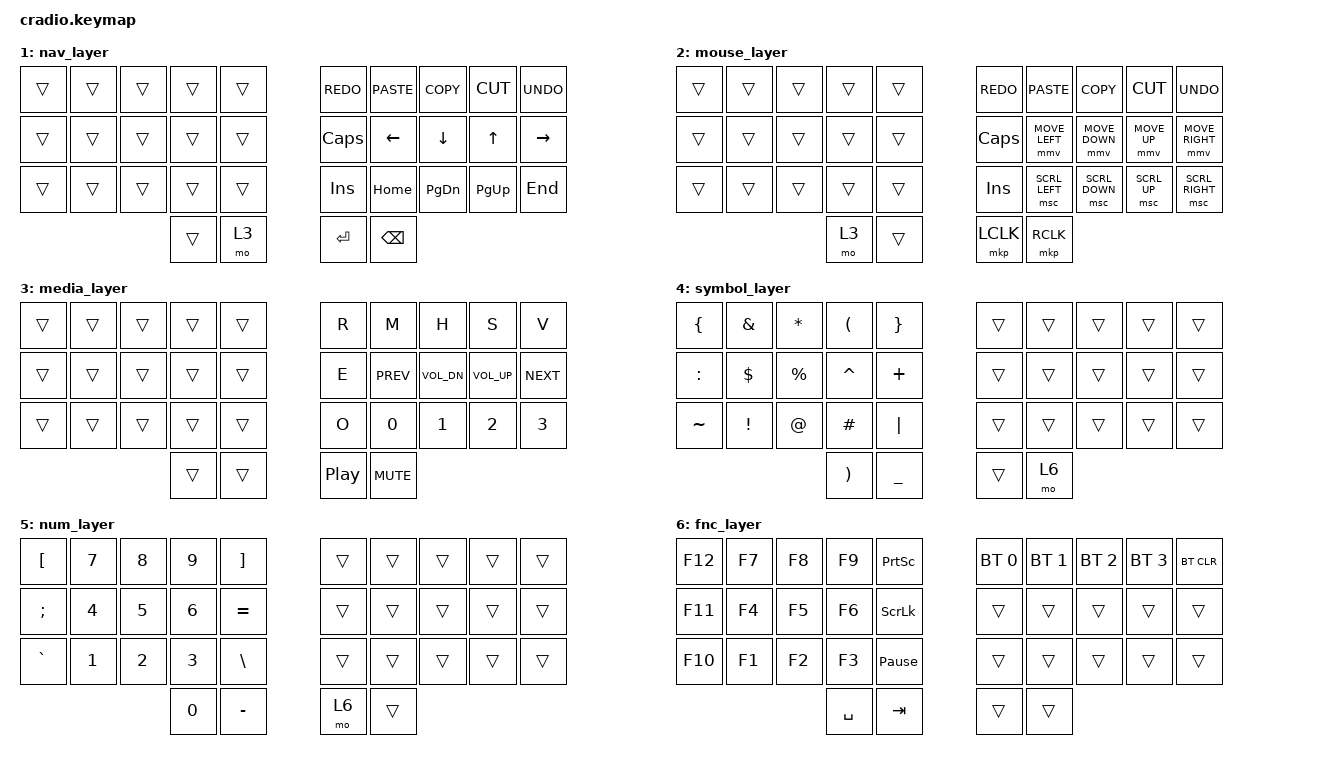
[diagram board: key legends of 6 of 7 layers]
// Copyright (c) 2022 The ZMK Contributors
// SPDX-License-Identifier: MIT

#include <behaviors.dtsi>
#include <dt-bindings/zmk/keys.h>
#include <dt-bindings/zmk/bt.h>
#include <dt-bindings/zmk/pointing.h>

// Home row mods macro
#define HRML(k1,k2,k3,k4) &ht LGUI k1  &ht LALT k2  &ht LCTRL k3  &ht LSHFT k4
#define HRMR(k1,k2,k3,k4) &ht RSHFT k1  &ht RCTRL k2  &ht RALT k3  &ht RGUI k4

/ {
    behaviors {
        ht: hold_tap {
            compatible = "zmk,behavior-hold-tap";
            #binding-cells = <2>;
            flavor = "tap-preferred";
            tapping-term-ms = <220>;
            quick-tap-ms = <150>;
            require-prior-idle-ms = <100>;
            bindings = <&kp>, <&kp>;
        };
    };


    combos {
                compatible = "zmk,combos";
                combo_esc {
                        timeout-ms = <75>;
                        key-positions = <0 1>;
                        bindings = <&kp ESC>;
                };
                combo_bksp {
                        timeout-ms = <75>;
                        key-positions = <8 9>;
                        bindings = <&kp BSPC>;
                };
                combo_entr {
                        timeout-ms = <75>;
                        key-positions = <28 29>;
                        bindings = <&kp RET>;
                };
                combo_tab {
                        timeout-ms = <75>;
                        key-positions = <20 21>;
                        bindings = <&kp TAB>;
                };
                //combo_mo_3 {
                //    timeout-ms = <75>;
                //    key-positions = <30, 31>;
                //    bindings = <&mo 3>;
                //};
                //combo_mo_6 {
                //    timeout-ms = <75>;
                //    key-positions = <32, 33>;
                //    bindings = <&mo 6>;
                //};
        };

    keymap {
        compatible = "zmk,keymap";
        default_layer {
            bindings = <
        //╭──────────┬──────────┬──────────┬──────────┬──────────╮   ╭──────────┬──────────┬──────────┬──────────┬──────────╮
        //│  Q       │  W       │  F       │  P       │  B       │   │  J       │  L       │  U       │  Y       │  '       │
            &kp Q      &kp W      &kp F      &kp P      &kp B          &kp J      &kp L      &kp U      &kp Y      &kp SQT
        //├──────────┼──────────┼──────────┼──────────┼──────────┤   ├──────────┼──────────┼──────────┼──────────┼──────────┤
        //│  A       │  R       │  S       │  T       │  G       │   │  M       │  N       │  E       │  I       │  O      │
            HRML(A,        R,         S,         T)     &kp G          &kp M      HRMR(N,        E,         I,        O)
        //├──────────┼──────────┼──────────┼──────────┼──────────┤   ├──────────┼──────────┼──────────┼──────────┼──────────┤
        //│  Z       │  X       │  C       │  D       │  V       │   │  K       │  H       │ , <      │ . >      │ / ?      │
            &kp Z      &kp X      &kp C      &kp D      &kp V          &kp K      &kp H      &kp COMMA  &kp DOT    &kp FSLH
        //╰──────────┴──────────┴──────────┼──────────┼──────────┤   ├──────────┼──────────┼──────────┴──────────┴──────────╯
                                            &lt 1 SPACE   &lt 2 TAB   &lt 4 ENTER  &lt 5 BSPC
        //                                 ╰──────────┴──────────╯   ╰──────────┴──────────╯
            >;
        };

        nav_layer {
            bindings = <
        //╭──────────┬──────────┬──────────┬──────────┬──────────╮   ╭──────────┬──────────┬──────────┬──────────┬──────────╮
        //│trans     │  trans   |          │          │          │   │ CUT     │ PAGE DN  │ PAGE UP  │ END      │  :       │
            &trans    &trans     &trans    &trans     &trans          &kp K_REDO &kp K_PASTE &kp K_COPY &kp K_CUT &kp K_UNDO
        //├──────────┼──────────┼──────────┼──────────┼──────────┤   ├──────────┼──────────┼──────────┼──────────┼──────────┤
        //│          │          │          │          │          │   │ LEFT     │ DOWN     │ UP       │ RIGHT    │  ;       │
            &trans    &trans     &trans     &trans     &trans         &kp CAPS  &kp LEFT   &kp DOWN   &kp UP   &kp RIGHT
        //├──────────┼──────────┼──────────┼──────────┼──────────┤   ├──────────┼──────────┼──────────┼──────────┼──────────┤
        //│          │          │          │          │          │   │          │          │          │          │          │
           &trans      &trans     &trans     &trans     &trans         &kp INS    &kp HOME   &kp PG_DN  &kp PG_UP  &kp END
        //╰──────────┴──────────┴──────────┼──────────┼──────────┤   ├──────────┼──────────┼──────────┴──────────┴──────────╯
                                             &trans     &mo 3        &kp ENTER   &kp BSPC
        //                                 ╰──────────┴──────────╯   ╰──────────┴──────────╯
            >;
        };

        mouse_layer {
            bindings = <
        //╭──────────┬──────────┬──────────┬──────────┬──────────╮   ╭──────────┬──────────┬──────────┬──────────┬──────────╮
        //│trans     │  trans   |          │          │          │   │ CUT     │ PAGE DN  │ PAGE UP  │ END      │  :       │
            &trans    &trans     &trans    &trans     &trans          &kp K_REDO &kp K_PASTE &kp K_COPY &kp K_CUT &kp K_UNDO
        //├──────────┼──────────┼──────────┼──────────┼──────────┤   ├──────────┼──────────┼──────────┼──────────┼──────────┤
        //│          │          │          │          │          │   │ LEFT     │ DOWN     │ UP       │ RIGHT    │  ;       │
            &trans    &trans     &trans     &trans     &trans         &kp CAPS &mmv MOVE_LEFT &mmv MOVE_DOWN &mmv MOVE_UP &mmv MOVE_RIGHT
        //├──────────┼──────────┼──────────┼──────────┼──────────┤   ├──────────┼──────────┼──────────┼──────────┼──────────┤
        //│          │          │          │          │          │   │          │          │          │          │          │
           &trans      &trans     &trans     &trans     &trans         &kp INS   &msc SCRL_LEFT &msc SCRL_DOWN &msc SCRL_UP &msc SCRL_RIGHT
        //╰──────────┴──────────┴──────────┼──────────┼──────────┤   ├──────────┼──────────┼──────────┴──────────┴──────────╯
                                             &mo 3     &trans        &mkp LCLK  &mkp RCLK
        //                                 ╰──────────┴──────────╯   ╰──────────┴──────────╯
            >;
        };

        media_layer {
            bindings = <
        //╭──────────┬──────────┬──────────┬──────────┬──────────╮   ╭──────────┬──────────┬──────────┬──────────┬──────────╮
        //│trans     │  trans   |          │          │          │   │ CUT     │ PAGE DN  │ PAGE UP  │ END      │  :       │
            &trans    &trans     &trans    &trans     &trans          &kp R     &kp M       &kp H       &kp S       &kp V
        //├──────────┼──────────┼──────────┼──────────┼──────────┤   ├──────────┼──────────┼──────────┼──────────┼──────────┤
        //│          │          │          │          │          │   │ LEFT     │ DOWN     │ UP       │ RIGHT    │  ;       │
            &trans    &trans     &trans     &trans     &trans         &kp E      &kp C_PREV &kp C_VOL_DN &kp C_VOL_UP &kp C_NEXT
        //├──────────┼──────────┼──────────┼──────────┼──────────┤   ├──────────┼──────────┼──────────┼──────────┼──────────┤
        //│          │          │          │          │          │   │          │          │          │          │          │
           &trans      &trans     &trans     &trans     &trans         &kp O   &kp 0 &kp 1 &kp 2 &kp 3
        //╰──────────┴──────────┴──────────┼──────────┼──────────┤   ├──────────┼──────────┼──────────┴──────────┴──────────╯
                                             &trans     &trans        &kp C_PP  &kp C_MUTE
        //                                 ╰──────────┴──────────╯   ╰──────────┴──────────╯
            >;
        };

        symbol_layer {
            bindings = <
        //╭──────────┬──────────┬──────────┬──────────┬──────────╮   ╭──────────┬──────────┬──────────┬──────────┬──────────╮
        //│trans     │  trans   |          │          │          │   │ CUT     │ PAGE DN  │ PAGE UP  │ END      │  :       │
            &kp LBRC    &kp AMPS    &kp ASTRK      &kp LPAR    &kp RBRC          &trans    &trans       &trans       &trans       &trans
        //├──────────┼──────────┼──────────┼──────────┼──────────┤   ├──────────┼──────────┼──────────┼──────────┼──────────┤
        //│          │          │          │          │          │   │ LEFT     │ DOWN     │ UP       │ RIGHT    │  ;       │
            &kp COLON    &kp DOLLAR  &kp PERCENT    &kp CARET   &kp PLUS         &trans      &trans &trans &trans &trans
        //├──────────┼──────────┼──────────┼──────────┼──────────┤   ├──────────┼──────────┼──────────┼──────────┼──────────┤
        //│          │          │          │          │          │   │          │          │          │          │          │
           &kp TILDE   &kp EXCL    &kp AT         &kp HASH    &kp PIPE         &trans   &trans &trans &trans &trans
        //╰──────────┴──────────┴──────────┼──────────┼──────────┤   ├──────────┼──────────┼──────────┴──────────┴──────────╯
                                             &kp RPAR     &kp UNDER        &trans  &mo 6
        //                                 ╰──────────┴──────────╯   ╰──────────┴──────────╯
            >;
        };

        num_layer {
            bindings = <
        //╭──────────┬──────────┬──────────┬──────────┬──────────╮   ╭──────────┬──────────┬──────────┬──────────┬──────────╮
        //│trans     │  trans   |          │          │          │   │ CUT     │ PAGE DN  │ PAGE UP  │ END      │  :       │
            &kp LBKT    &kp N7    &kp N8    &kp N9    &kp RBKT          &trans    &trans       &trans       &trans       &trans
        //├──────────┼──────────┼──────────┼──────────┼──────────┤   ├──────────┼──────────┼──────────┼──────────┼──────────┤
        //│          │          │          │          │          │   │ LEFT     │ DOWN     │ UP       │ RIGHT    │  ;       │
           &kp SEMI    &kp N4    &kp N5    &kp N6    &kp EQUAL         &trans      &trans &trans &trans &trans
        //├──────────┼──────────┼──────────┼──────────┼──────────┤   ├──────────┼──────────┼──────────┼──────────┼──────────┤
        //│          │          │          │          │          │   │          │          │          │          │          │
           &kp GRAVE   &kp N1    &kp N2    &kp N3    &kp BSLH         &trans   &trans &trans &trans &trans
        //╰──────────┴──────────┴──────────┼──────────┼──────────┤   ├──────────┼──────────┼──────────┴──────────┴──────────╯
                                             &kp N0       &kp MINUS        &mo 6  &trans
        //                                 ╰──────────┴──────────╯   ╰──────────┴──────────╯
            >;
        };

        fnc_layer {
            bindings = <
        //╭──────────┬──────────┬──────────┬──────────┬──────────╮   ╭──────────┬──────────┬──────────┬──────────┬──────────╮
        //│trans     │  trans   |          │          │          │   │ CUT     │ PAGE DN  │ PAGE UP  │ END      │  :       │
            &kp F12    &kp F7    &kp F8    &kp F9    &kp PSCRN        &bt BT_SEL 0 &bt BT_SEL 1   &bt BT_SEL 2  &bt BT_SEL 3  &bt BT_CLR
        //├──────────┼──────────┼──────────┼──────────┼──────────┤   ├──────────┼──────────┼──────────┼──────────┼──────────┤
        //│          │          │          │          │          │   │ LEFT     │ DOWN     │ UP       │ RIGHT    │  ;       │
           &kp F11    &kp F4    &kp F5    &kp F6    &kp  SLCK        &trans      &trans &trans &trans &trans
        //├──────────┼──────────┼──────────┼──────────┼──────────┤   ├──────────┼──────────┼──────────┼──────────┼──────────┤
        //│          │          │          │          │          │   │          │          │          │          │          │
           &kp F10   &kp F1    &kp F2    &kp F3    &kp PAUSE_BREAK        &trans   &trans &trans &trans &trans
        //╰──────────┴──────────┴──────────┼──────────┼──────────┤   ├──────────┼──────────┼──────────┴──────────┴──────────╯
                                             &kp SPACE       &kp TAB        &trans  &trans
        //                                 ╰──────────┴──────────╯   ╰──────────┴──────────╯
            >;
        };
    };
};
